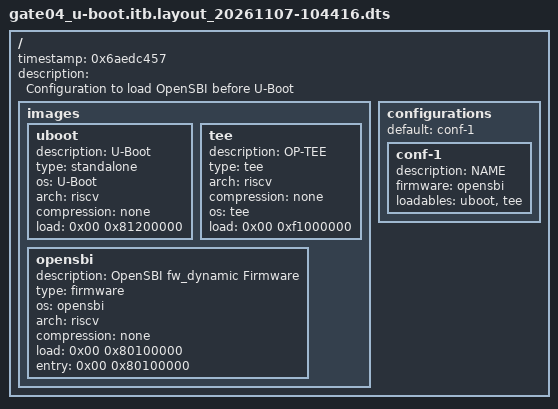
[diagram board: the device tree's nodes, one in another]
/dts-v1/;

/ {
	timestamp = <0x6aedc457>;
	description = "Configuration to load OpenSBI before U-Boot";
	#address-cells = <0x02>;

	images {

		uboot {
			description = "U-Boot";
			type = "standalone";
			os = "U-Boot";
			arch = "riscv";
			compression = "none";
			load = <0x00 0x81200000>;
		};

		tee {
			description = "OP-TEE";
			type = "tee";
			arch = "riscv";
			compression = "none";
			os = "tee";
			load = <0x00 0xf1000000>;
		};

		opensbi {
			description = "OpenSBI fw_dynamic Firmware";
			type = "firmware";
			os = "opensbi";
			arch = "riscv";
			compression = "none";
			load = <0x00 0x80100000>;
			entry = <0x00 0x80100000>;
		};
	};

	configurations {
		default = "conf-1";

		conf-1 {
			description = "NAME";
			firmware = "opensbi";
			loadables = "uboot", "tee";
		};
	};
};
